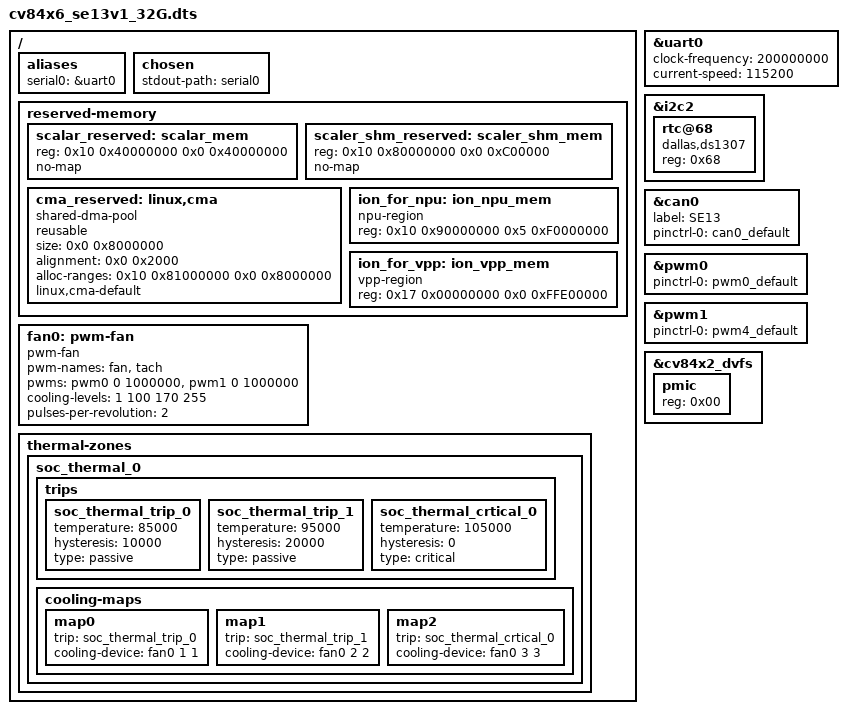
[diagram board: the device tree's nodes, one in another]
/dts-v1/;
#include "soph_base_arm64.dtsi"
#include "soph_asic_emmc.dtsi"
#include "soph_base.dtsi"
#include "soph_default_memmap_32G.dtsi"

/ {
	aliases {
		serial0 = &uart0;
	};

	chosen {
		stdout-path = "serial0"; // "serial0:115200n8", no arguments means no re-initialization
	};
	reserved-memory {
		#address-cells = <0x2>;
		#size-cells = <0x2>;
		ranges;

#ifndef __UBOOT__
		scalar_reserved: scalar_mem {
			reg = <0x10 0x40000000 0x0 0x40000000>;	//1GB for 4x256M TPU firmware
			no-map;
		};
		scaler_shm_reserved: scaler_shm_mem {
			reg = <0x10 0x80000000 0x0 0xC00000>;	//12MB after scalar parks
			no-map;
		};

		cma_reserved: linux,cma {
			compatible = "shared-dma-pool";
			reusable;
			size = <0x0 0x8000000>; // 128MB
			alignment = <0x0 0x2000>; // 8KB
			alloc-ranges = <0x10 0x81000000 0x0 0x8000000>;
			linux,cma-default;
		};
		ion_for_npu: ion_npu_mem {
			compatible = "npu-region";
			reg = <0x10 0x90000000 0x5 0xF0000000>; // 23.75GB for TPU (end kept at 0x1680000000)
		};

		ion_for_vpp: ion_vpp_mem {
			compatible = "vpp-region";
			reg = <0x17 0x00000000 0x0 0xFFE00000>; // 4GB for VPP (full Node7, 2MB reserved for FREERTOS)
		};

#endif
	};

	fan0: pwm-fan {
		compatible = "pwm-fan";
		#cooling-cells = <2>;
		pwm-names = "fan", "tach";
		pwms = <&pwm0 0 1000000>, /* pwm0 ch0: fan */
		       <&pwm1 0 1000000>; /* pwm1 ch0: tach (PWM4) */
		cooling-levels = <1 100 170 255>;
		pulses-per-revolution = <2>;
	};

	thermal-zones {
		soc_thermal_0 {
			trips {
				soc_thermal_trip_0: soc_thermal_trip_0 {
					temperature = <85000>; /* millicelsius */
					hysteresis = <10000>; /* millicelsius */
					type = "passive";
				};

				soc_thermal_trip_1: soc_thermal_trip_1 {
					temperature = <95000>; /* millicelsius */
					hysteresis = <20000>; /* millicelsius */
					type = "passive";
				};

				soc_thermal_crtical_0: soc_thermal_crtical_0 {
					temperature = <105000>; /* millicelsius */
					hysteresis = <0>; /* millicelsius */
					type = "critical";
				};
			};
			cooling-maps {
				map0 {
					trip = <&soc_thermal_trip_0>;
					cooling-device = <&fan0 1 1>;
				};

				map1 {
					trip = <&soc_thermal_trip_1>;
					cooling-device = <&fan0 2 2>;
				};

				map2 {
					trip = <&soc_thermal_crtical_0>;
					cooling-device = <&fan0 3 3>;
				};
			};
		};
	};
};

&uart0 {
	clock-frequency = <200000000>;
	current-speed = <115200>;
};

&i2c2 {
	rtc@68 {
		compatible = "dallas,ds1307";
		reg = <0x68>;
	};
};

&can0 {
	label = "SE13";
};

&can0 {
	pinctrl-names = "default";
	pinctrl-0 = <&can0_default>;
	label = "SE13";
};

&pwm0 {
	pinctrl-names = "default";
	pinctrl-0 = <&pwm0_default>;
};

&pwm1 {
	pinctrl-names = "default";
	pinctrl-0 = <&pwm4_default>;
};

&cv84x2_dvfs {
	pmic {
		reg = <0x00>;	/* SE13: JWH PMIC @ 0x00 */
	};
};

